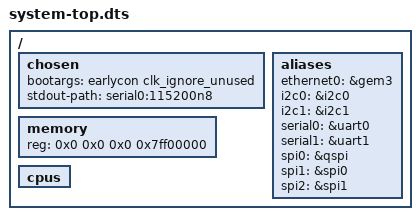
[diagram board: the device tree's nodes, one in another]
/*
 * CAUTION: This file is automatically generated by Xilinx.
 * Version: XSCT 2019.2
 * Today is: Mon Aug 31 17:20:10 2020
 */


/dts-v1/;
#include "zynqmp.dtsi"
#include "zynqmp-clk-ccf.dtsi"
#include "pcw.dtsi"
/ {
	chosen {
		bootargs = "earlycon clk_ignore_unused";
		stdout-path = "serial0:115200n8";
	};
	aliases {
		ethernet0 = &gem3;
		i2c0 = &i2c0;
		i2c1 = &i2c1;
		serial0 = &uart0;
		serial1 = &uart1;
		spi0 = &qspi;
		spi1 = &spi0;
		spi2 = &spi1;
	};
	memory {
		device_type = "memory";
		reg = <0x0 0x0 0x0 0x7ff00000>;
	};
	cpus {
		/delete-node/ cpu@2 ;
		/delete-node/ cpu@3 ;
	};
};
